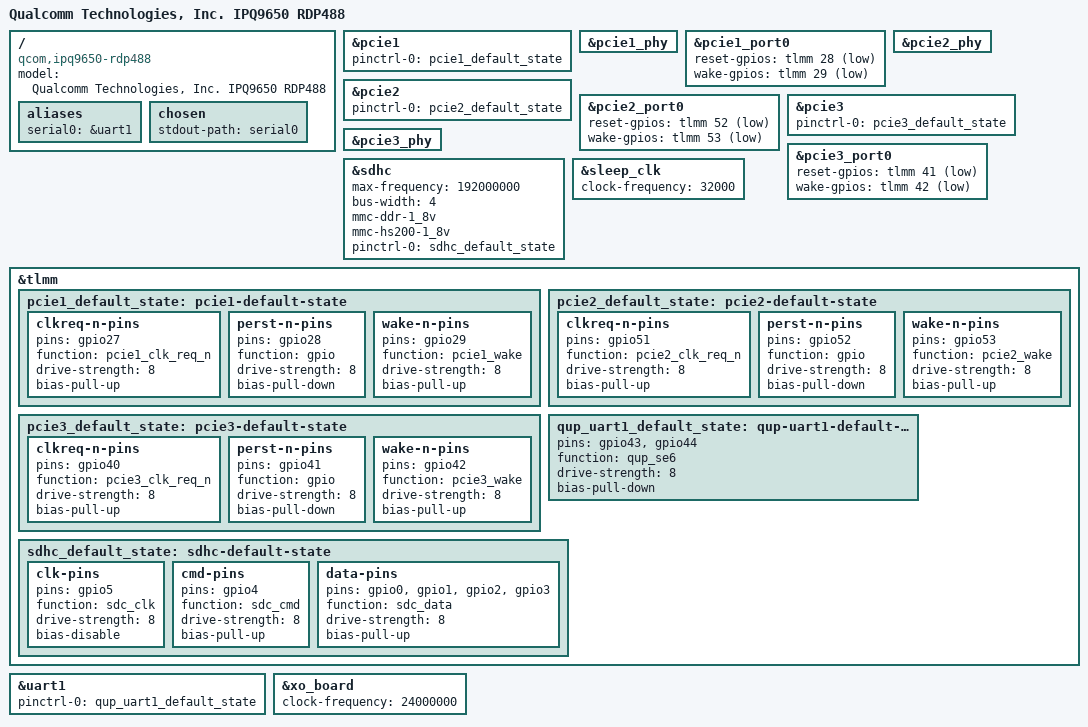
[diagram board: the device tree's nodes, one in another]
// SPDX-License-Identifier: BSD-3-Clause
/*
 * Copyright (c) Qualcomm Technologies, Inc. and/or its subsidiaries.
 */

/dts-v1/;

#include <dt-bindings/gpio/gpio.h>

#include "ipq9650.dtsi"

/ {
	model = "Qualcomm Technologies, Inc. IPQ9650 RDP488";
	compatible = "qcom,ipq9650-rdp488", "qcom,ipq9650";

	aliases {
		serial0 = &uart1;
	};

	chosen {
		stdout-path = "serial0";
	};
};

&pcie1 {
	pinctrl-0 = <&pcie1_default_state>;
	pinctrl-names = "default";

	status = "okay";
};

&pcie1_phy {
	status = "okay";
};

&pcie1_port0 {
	reset-gpios = <&tlmm 28 GPIO_ACTIVE_LOW>;
	wake-gpios = <&tlmm 29 GPIO_ACTIVE_LOW>;
};

&pcie2 {
	pinctrl-0 = <&pcie2_default_state>;
	pinctrl-names = "default";

	status = "okay";
};

&pcie2_phy {
	status = "okay";
};

&pcie2_port0 {
	reset-gpios = <&tlmm 52 GPIO_ACTIVE_LOW>;
	wake-gpios = <&tlmm 53 GPIO_ACTIVE_LOW>;
};

&pcie3 {
	pinctrl-0 = <&pcie3_default_state>;
	pinctrl-names = "default";

	status = "okay";
};

&pcie3_phy {
	status = "okay";
};

&pcie3_port0 {
	reset-gpios = <&tlmm 41 GPIO_ACTIVE_LOW>;
	wake-gpios = <&tlmm 42 GPIO_ACTIVE_LOW>;
};

&sdhc {
	max-frequency = <192000000>;
	bus-width = <4>;
	mmc-ddr-1_8v;
	mmc-hs200-1_8v;
	pinctrl-0 = <&sdhc_default_state>;
	pinctrl-names = "default";

	status = "okay";
};

&sleep_clk {
	clock-frequency = <32000>;
};

&tlmm {
	pcie1_default_state: pcie1-default-state {
		clkreq-n-pins {
			pins = "gpio27";
			function = "pcie1_clk_req_n";
			drive-strength = <8>;
			bias-pull-up;
		};

		perst-n-pins {
			pins = "gpio28";
			function = "gpio";
			drive-strength = <8>;
			bias-pull-down;
		};

		wake-n-pins {
			pins = "gpio29";
			function = "pcie1_wake";
			drive-strength = <8>;
			bias-pull-up;
		};
	};

	pcie2_default_state: pcie2-default-state {
		clkreq-n-pins {
			pins = "gpio51";
			function = "pcie2_clk_req_n";
			drive-strength = <8>;
			bias-pull-up;
		};

		perst-n-pins {
			pins = "gpio52";
			function = "gpio";
			drive-strength = <8>;
			bias-pull-down;
		};

		wake-n-pins {
			pins = "gpio53";
			function = "pcie2_wake";
			drive-strength = <8>;
			bias-pull-up;
		};
	};

	pcie3_default_state: pcie3-default-state {
		clkreq-n-pins {
			pins = "gpio40";
			function = "pcie3_clk_req_n";
			drive-strength = <8>;
			bias-pull-up;
		};

		perst-n-pins {
			pins = "gpio41";
			function = "gpio";
			drive-strength = <8>;
			bias-pull-down;
		};

		wake-n-pins {
			pins = "gpio42";
			function = "pcie3_wake";
			drive-strength = <8>;
			bias-pull-up;
		};
	};

	qup_uart1_default_state: qup-uart1-default-state {
		pins = "gpio43", "gpio44";
		function = "qup_se6";
		drive-strength = <8>;
		bias-pull-down;
	};

	sdhc_default_state: sdhc-default-state {
		clk-pins {
			pins = "gpio5";
			function = "sdc_clk";
			drive-strength = <8>;
			bias-disable;
		};

		cmd-pins {
			pins = "gpio4";
			function = "sdc_cmd";
			drive-strength = <8>;
			bias-pull-up;
		};

		data-pins {
			pins = "gpio0", "gpio1", "gpio2", "gpio3";
			function = "sdc_data";
			drive-strength = <8>;
			bias-pull-up;
		};
	};
};

&uart1 {
	pinctrl-0 = <&qup_uart1_default_state>;
	pinctrl-names = "default";

	status = "okay";
};

&xo_board {
	clock-frequency = <24000000>;
};
